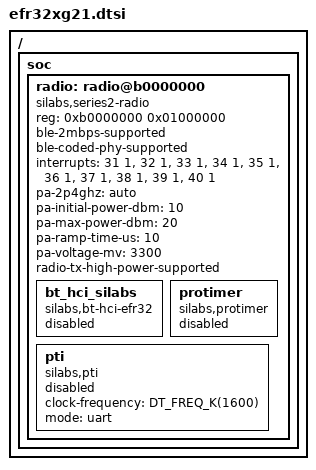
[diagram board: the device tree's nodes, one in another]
/*
 * Copyright (c) 2025 Silicon Laboratories Inc.
 *
 * SPDX-License-Identifier: Apache-2.0
 */

#include <silabs/xg21/xg21.dtsi>

/ {
	soc {
		radio: radio@b0000000 {
			compatible = "silabs,series2-radio";
			reg = <0xb0000000 0x01000000>;
			ble-2mbps-supported;
			ble-coded-phy-supported;
			interrupt-names = "agc", "bufc", "frc_pri", "frc", "modem", "protimer",
					  "rac_rsm", "rac_seq", "prortc", "synth";
			interrupts = <31 1>, <32 1>, <33 1>, <34 1>, <35 1>, <36 1>, <37 1>,
				     <38 1>, <39 1>, <40 1>;
			pa-2p4ghz = "auto";
			pa-initial-power-dbm = <10>;
			pa-max-power-dbm = <20>;
			pa-ramp-time-us = <10>;
			pa-voltage-mv = <3300>;
			radio-tx-high-power-supported;

			bt_hci_silabs: bt_hci_silabs {
				compatible = "silabs,bt-hci-efr32";
				status = "disabled";
			};

			protimer: protimer {
				compatible = "silabs,protimer";
				status = "disabled";
			};

			pti: pti {
				compatible = "silabs,pti";
				clock-frequency = <DT_FREQ_K(1600)>;
				mode = "uart";
				status = "disabled";
			};
		};
	};
};
